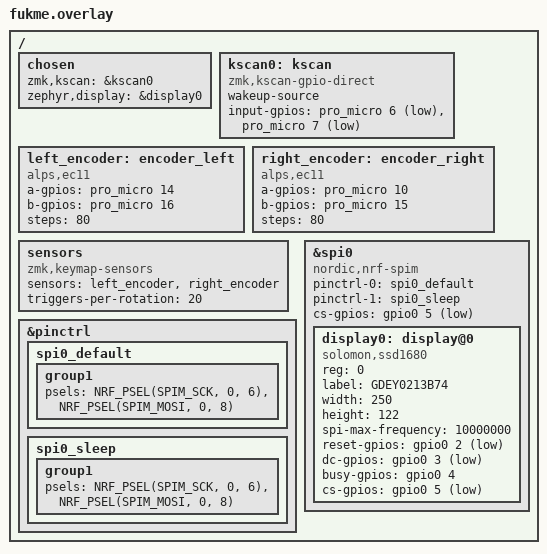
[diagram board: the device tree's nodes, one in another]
/ {
    chosen {
        zmk,kscan = &kscan0;
        zephyr,display = &display0;
        
        // Other chosen items
    };

    kscan0: kscan {
        compatible = "zmk,kscan-gpio-direct";
        wakeup-source;
        input-gpios
            = <&pro_micro 6 (GPIO_ACTIVE_LOW | GPIO_PULL_UP)>
            , <&pro_micro 7 (GPIO_ACTIVE_LOW | GPIO_PULL_UP)>
            ;
    };

    left_encoder: encoder_left {
        compatible = "alps,ec11";
        a-gpios = <&pro_micro 14 (GPIO_ACTIVE_HIGH | GPIO_PULL_UP)>;
        b-gpios = <&pro_micro 16 (GPIO_ACTIVE_HIGH | GPIO_PULL_UP)>;
        steps = <80>;
        status = "okay";
    };

    right_encoder: encoder_right {
        compatible = "alps,ec11";
        a-gpios = <&pro_micro 10 (GPIO_ACTIVE_HIGH)>;
        b-gpios = <&pro_micro 15 (GPIO_ACTIVE_HIGH)>;
        steps = <80>;
        status = "okay";
    };


    sensors: sensors {
        compatible = "zmk,keymap-sensors";
        sensors = <&left_encoder &right_encoder>;
        triggers-per-rotation = <20>;
    };

    &pinctrl{

        spi0_default: spi0_default {
             group1 {
                /* main role: configure P0.01 as SPI clock, P0.02 as SPI MOSI, P0.03 as SPI MISO */
                psels = <NRF_PSEL(SPIM_SCK, 0, 6)>,
                        <NRF_PSEL(SPIM_MOSI, 0, 8)>;
            };
        };

        spi0_sleep: spi0_sleep {
            group1 {
                /* main role: configure P0.01 as SPI clock, P0.02 as SPI MOSI, P0.03 as SPI MISO */
                psels = <NRF_PSEL(SPIM_SCK, 0, 6)>,
                        <NRF_PSEL(SPIM_MOSI, 0, 8)>,
                low-power-enable;
            };
        };
    };

    &spi0 {
        compatible = "nordic,nrf-spim";
        pinctrl-0 = <&spi0_default>;
        pinctrl-1 = <&spi0_sleep>;
        pinctrl-names = "default", "sleep";

        status = "okay";
        cs-gpios = <&gpio0 5 GPIO_ACTIVE_LOW>;

        display0: display@0 {
            compatible = "solomon,ssd1680";
            reg = <0>;
            label = "GDEY0213B74";
            width = <250>;
            height = <122>;
            spi-max-frequency = <10000000>;
            reset-gpios = <&gpio0 2 GPIO_ACTIVE_LOW>;
            dc-gpios = <&gpio0 3 GPIO_ACTIVE_LOW>;
            busy-gpios = <&gpio0 4 GPIO_ACTIVE_HIGH>;
            cs-gpios = <&gpio0 5 GPIO_ACTIVE_LOW>;
        };
    };
    
};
